# STMP3770 register map
Vendor: Freescale Semiconductor (NXP); Series: STMP37xx; File version: 1.0
CPU: other r0p0, little endian, no MPU, no FPU, 2 interrupt priority bits
Registers are 32-bit, read-write, reset 0x0 unless marked. A register's access mark holds for its fields unless they carry their own. Offsets are from the block's base; [hi:lo] are bit positions.

## SSP1 — 同步串行端口 1(SSP,支持 SD/MMC 卡与 SPI 主/从模式)
Base 0x80010000
Same registers: SSP2 0x80034000
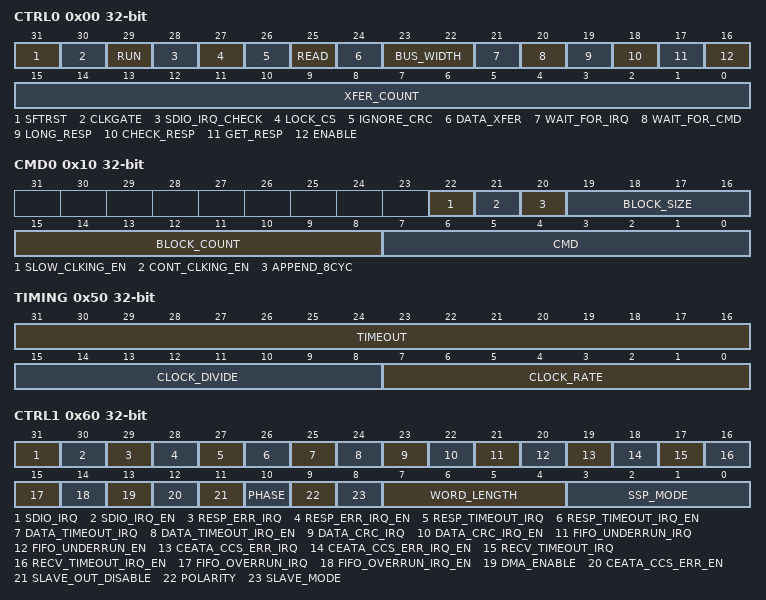
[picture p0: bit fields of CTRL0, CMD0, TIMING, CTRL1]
0x00 CTRL0 — SSP Control Register 0
  [31] SFTRST — SSP Reset. 0=not reset, 1=held in reset. Registers returned to reset state. Min reset time = max(6 APBCLK, 2 SSPCLK) cycles. Bits[31] RW Reset=0x1
  [30] CLKGATE — Gate SSP Clocks. 0=clocks not gated, 1=clocks gated. Set to save power while SSP not actively used. Bits[30] RW Reset=0x1
  [29] RUN — SSP Run. 0=not running, 1=running. Automatically set during DMA operation. Bits[29] RW Reset=0x0
  [28] SDIO_IRQ_CHECK — SD/MMC: enable SDIO IRQ. CE_ATA: 0=ignore CCS, 1=wait for CCS. Must not be 1 if LOCK_CS=1. Bits[28] RW Reset=0x0
  [27] LOCK_CS — SPI: 0=deassert CS, 1=hold CS. SD/MMC: 0=check CRC status, 1=ignore CRC. CE_ATA: disable CCS. If set, DATA_XFER must also be set. Bits[27] RW Reset=0x0
  [26] IGNORE_CRC — Ignore Response CRC in SD/MMC and MS modes. Bits[26] RW Reset=0x0
  [25] READ — Read Mode. When set with DATA_XFER, SSP reads from device. Otherwise SSP writes to device. Bits[25] RW Reset=0x0
  [24] DATA_XFER — Data Transfer Mode. When set, transfers XFER_COUNT bytes of data. MS mode: 1=use FIFOs, 0=use Resp0/Cmd1 registers. Bits[24] RW Reset=0x0
  [23:22] BUS_WIDTH — Data Bus Width. ONE_BIT=0x0, FOUR_BIT=0x1, EIGHT_BIT=0x2. SD/MMC/CE_ATA support all; MS 1/4-bit; SPI 1-bit. Bits[23:22] RW Reset=0x0
    0=ONE_BIT; 1=FOUR_BIT; 2=EIGHT_BIT
  [21] WAIT_FOR_IRQ — MS: wait for card IRQ before TPC. SD/MMC: wait for MMC ready before sending command. Bits[21] RW Reset=0x0
  [20] WAIT_FOR_CMD — SD/MMC: 0=send commands immediately, 1=wait until CRC-checking of data transfer completes. Used to send STOP during multi-block read. Bits[20] RW Reset=0x0
  [19] LONG_RESP — SD/MMC: 0=short response, 1=136-bit long response. Only valid if GET_RESP set. Bits[19] RW Reset=0x0
  [18] CHECK_RESP — SD/MMC/MS: XOR response with REFERENCE, mask with MASK. Mismatch sets RESP_ERR and optionally RESP_ERR_IRQ. Bits[18] RW Reset=0x0
  [17] GET_RESP — SD/MMC/MS: 0=do not wait for card response, 1=command expects response from card. Bits[17] RW Reset=0x0
  [16] ENABLE — SD/MMC/MS Command Transmit Enable. 0=commands disabled, 1=data in Command registers will be sent. Bits[16] RW Reset=0x0
  [15:0] XFER_COUNT — Number of words to transfer per WORD_LENGTH in CTRL1. Run bit and DMA request clear after transfer. SD/MMC: multiple of block size. Bits[15:0] RW Reset=0x1
0x10 CMD0 — SD/MMC and MS Command Register 0
  [22] SLOW_CLKING_EN — SLOW_CLKING_EN。注：PDF第16.11.2节Table 752将bit 31:21标记为RSVD，此字段可能来自后续芯片修订。
  [21] CONT_CLKING_EN — CONT_CLKING_EN。注：PDF第16.11.2节Table 752将bit 31:21标记为RSVD，此字段可能来自后续芯片修订。
  [20] APPEND_8CYC — SD/MMC/CE_ATA: 0=SCK toggles up to 4 cycles idle, 1=8 more cycles. Set to 1 at end of block transfer. Bits[20] RW Reset=0x0
  [19:16] BLOCK_SIZE — SD/MMC block size encode. When BLOCK_COUNT!=0, size = (1<<BLOCK_SIZE). When BLOCK_COUNT=0, ignored. Bits[19:16] RW Reset=0x0
  [15:8] BLOCK_COUNT — SD/MMC block count minus one. Equation: XFER_COUNT = (1<<BLOCK_SIZE)*(BLOCK_COUNT+1). Also SPI control word[15:8]. Bits[15:8] RW Reset=0x0
  [7:0] CMD — SD/MMC Command Index (bits 5:0) or MS TPC[7:0] to send to card. Also SPI control word[7:0]. Includes all standard MMC/SD commands. Bits[7:0] RW Reset=0x0
    0=MMC_GO_IDLE_STATE; 1=MMC_SEND_OP_COND; 2=MMC_ALL_SEND_CID; 3=MMC_SET_RELATIVE_ADDR; 4=MMC_SET_DSR; 5=MMC_RESERVED_5; 6=MMC_SWITCH; 7=MMC_SELECT_DESELECT_CARD; 8=MMC_SEND_EXT_CSD; 9=MMC_SEND_CSD; 10=MMC_SEND_CID; 11=MMC_READ_DAT_UNTIL_STOP; 12=MMC_STOP_TRANSMISSION; 13=MMC_SEND_STATUS; 14=MMC_BUSTEST_R; 15=MMC_GO_INACTIVE_STATE; 16=MMC_SET_BLOCKLEN; 17=MMC_READ_SINGLE_BLOCK; 18=MMC_READ_MULTIPLE_BLOCK; 19=MMC_BUSTEST_W; 20=MMC_WRITE_DAT_UNTIL_STOP; 23=MMC_SET_BLOCK_COUNT; 24=MMC_WRITE_BLOCK; 25=MMC_WRITE_MULTIPLE_BLOCK; 26=MMC_PROGRAM_CID; 27=MMC_PROGRAM_CSD; 28=MMC_SET_WRITE_PROT; 29=MMC_CLR_WRITE_PROT; 30=MMC_SEND_WRITE_PROT; 35=MMC_ERASE_GROUP_START; 36=MMC_ERASE_GROUP_END; 38=MMC_ERASE; 39=MMC_FAST_IO; 40=MMC_GO_IRQ_STATE; 42=MMC_LOCK_UNLOCK; 55=MMC_APP_CMD; 56=MMC_GEN_CMD; 32=SD_ERASE_WR_BLK_START; 33=SD_ERASE_WR_BLK_END; 52=SD_IO_RW_DIRECT; 53=SD_IO_RW_EXTENDED
0x20 CMD1 — SD/MMC Command Register 1
  [31:0] CMD_ARG — SD/MMC or MS Command Argument. Bits[31:0] RW Reset=0x0
0x30 COMPREF — SD/MMC and MS Compare Reference
  [31:0] REFERENCE — SD/MMC/MS compare reference. XOR'd with response when CHECK_RESP set, masked by MASK. Differences indicate error to DMA. Bits[31:0] RW Reset=0x0
0x40 COMPMASK — SD/MMC and MS compare mask
  [31:0] MASK — SD/MMC/MS Compare Mode Mask. Masks result of response vs REFERENCE comparison when CHECK_RESP set. Bits[31:0] RW Reset=0x0
0x50 TIMING — SSP Timing Register
  [31:16] TIMEOUT — Time-Out Counter. SCK cycles * 4096 before asserting DATA TIMEOUT IRQ. Used for SD/MMC and MS data transfer time-out. Bits[31:16] RW Reset=0x0
  [15:8] CLOCK_DIVIDE — Clock Pre-Divider. Must be even value from 2 to 254. Bits[15:8] RW Reset=0x0
  [7:0] CLOCK_RATE — Serial Clock Rate. Bit rate = SSPCLK / (CLOCK_DIVIDE * (1+CLOCK_RATE)). Value from 0 to 255. Bits[7:0] RW Reset=0x0
0x60 CTRL1 — SSP Control Register 1
  [31] SDIO_IRQ — SDIO card interrupt occurred. Write 1 to SET clear address to reset. Bits[31] RW Reset=0x0
  [30] SDIO_IRQ_EN — SDIO Card Interrupt IRQ Enable. 0=masked, 1=IRQs sent to ICOLL. Bits[30] RW Reset=0x0
  [29] RESP_ERR_IRQ — Unexpected response/CRC when CHECK_RESP set. Write 1 to SET clear address to reset. Bits[29] RW Reset=0x0
  [28] RESP_ERR_IRQ_EN — Card Error IRQ Enable. 0=masked, 1=enabled. Asserts CPU IRQ when card error bit set in both Error Mask and R1 response. Bits[28] RW Reset=0x0
  [27] RESP_TIMEOUT_IRQ — Command response time-out occurred. SD/MMC and MS handshake. Write 1 to SET clear address to reset. Bits[27] RW Reset=0x0
  [26] RESP_TIMEOUT_IRQ_EN — Response Time-Out IRQ Enable. 0=masked, 1=enabled. Asserts when no SD/MMC response in 64 cycles or MS not ready in 16 cycles. Bits[26] RW Reset=0x0
  [25] DATA_TIMEOUT_IRQ — Data transmit/receive time-out error IRQ. Counter expired before data bus ready. SD/MMC and MS only. Bits[25] RW Reset=0x0
  [24] DATA_TIMEOUT_IRQ_EN — Data Time-Out Error IRQ Enable. For SD/MMC and MS modes only. Bits[24] RW Reset=0x0
  [23] DATA_CRC_IRQ — Data CRC Error IRQ. For SD/MMC and MS modes only. Write 1 to SET clear address to reset. Bits[23] RW Reset=0x0
  [22] DATA_CRC_IRQ_EN — Data CRC Error IRQ Enable. For SD/MMC and MS modes only. Bits[22] RW Reset=0x0
  [21] FIFO_UNDERRUN_IRQ — FIFO Underrun Interrupt. Set when FIFO read while empty. Write 1 to SET clear address to reset. Bits[21] RW Reset=0x1
  [20] FIFO_UNDERRUN_EN — FIFO Underrun IRQ Enable. IRQ generated if set and FIFO_UNDERRUN_IRQ asserted. Bits[20] RW Reset=0x0
  [19] CEATA_CCS_ERR_IRQ — CE-ATA unexpected CCS error interrupt. Write 1 to SET clear address to reset. Bits[19] RW Reset=0x0
  [18] CEATA_CCS_ERR_IRQ_EN — CE-ATA Unexpected CCS Error Interrupt Enable. 0=disable, 1=enable. Bits[18] RW Reset=0x0
  [17] RECV_TIMEOUT_IRQ — Data Time-Out Interrupt. RX FIFO not empty but not read for 128 HCLK cycles. SPI modes only. Write 1 to SET clear to reset. Bits[17] RW Reset=0x0
  [16] RECV_TIMEOUT_IRQ_EN — Receive Time-Out IRQ Enable. IRQ if RX FIFO not empty and no read for 128 HCLK cycles. Bits[16] RW Reset=0x0
  [15] FIFO_OVERRUN_IRQ — FIFO Overrun Interrupt. Written while full. Write 1 to SET clear address to reset. Bits[15] RW Reset=0x0
  [14] FIFO_OVERRUN_IRQ_EN — FIFO Overrun Interrupt Enable. IRQ if FIFO written while full. Bits[14] RW Reset=0x0
  [13] DMA_ENABLE — DMA Enable. Enables DMA request and command end signals. Bits[13] RW Reset=0x0
  [12] CEATA_CCS_ERR_EN — CE-ATA unexpected CCS error enable. Enables error generation for unexpected CCS. Bits[12] RW Reset=0x0
  [11] SLAVE_OUT_DISABLE — Slave Output Disable. 0=SSP drives MISO in slave mode, 1=does not drive MISO. Bits[11] RW Reset=0x0
  [10] PHASE — Serial Clock Phase. For SPI mode only. Bits[10] RW Reset=0x0
  [9] POLARITY — Serial Clock Polarity. SD/MMC/MS: CMD/TX edge select. MS 1-bit=1, 4-bit=0. SPI: 0=steady 0, 1=steady 1 when idle. Bits[9] RW Reset=0x0
  [8] SLAVE_MODE — Slave Mode. 0=master, 1=slave. Clear to 0 for SD/MMC and MS modes. Bits[8] RW Reset=0x0
  [7:4] WORD_LENGTH — Word Length in bits. 0x0-0x2 reserved, 0x3=4b, 0x7=8b, 0xF=16b. Always 8b in SD/MMC/CE_ATA and MS. Bits[7:4] RW Reset=0x8
    3=FOUR_BITS; 7=EIGHT_BITS; 15=SIXTEEN_BITS
  [3:0] SSP_MODE — Operating Mode. 0x0=SPI, 0x1=TI SSI, 0x3=SD/MMC, 0x4=MS, 0x7=CE_ATA. Soft reset before changing. Bits[3:0] RW Reset=0x0
    0=SPI; 1=SSI; 3=SD_MMC; 4=MS; 7=CE_ATA
0x70 DATA — SSP Data Register
  [31:0] DATA — Data Register. Holds 1-4 words per WORD_LENGTH. Right-justified. Read increments RX FIFO; write increments TX FIFO. Bits[31:0] RW Reset=0x0
0x80 SDRESP0 — SD/MMC Card Response Register 0
  [31:0] RESP0 — SD/MMC Response Status Bits[31:0]. MS mode: device read data. Bits[31:0] RO Reset=0x0
0x90 SDRESP1 — SD/MMC Card Response Register 1
  [31:0] RESP1 — SD/MMC Short Response Command Index[37:32] or Long Response[63:32]. Bits[31:0] RO Reset=0x0
0xA0 SDRESP2 — SD/MMC Card Response Register 2
  [31:0] RESP2 — SD/MMC Long Response[95:64]. Bits[31:0] RO Reset=0x0
0xB0 SDRESP3 — SD/MMC Card Response Register 3
  [31:0] RESP3 — SD/MMC Long Response[127:96]. Bits[31:0] RO Reset=0x0
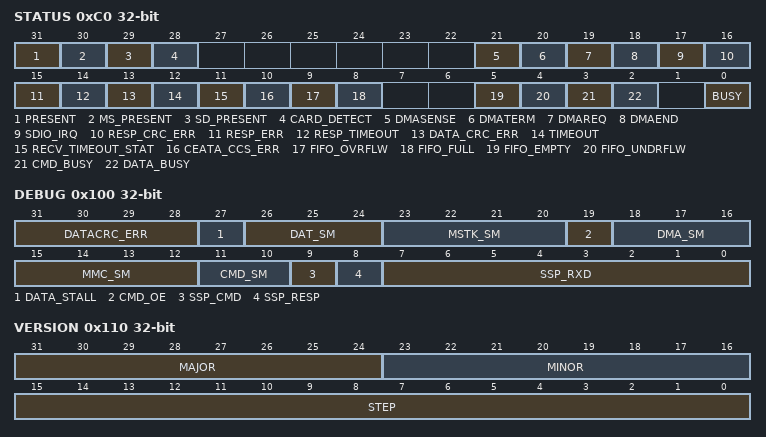
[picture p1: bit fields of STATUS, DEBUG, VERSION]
0xC0 STATUS ro — SSP Status Register
  [31] PRESENT — SSP Present. 0=not present in product, 1=present. Bits[31] RO Reset=0x1
  [30] MS_PRESENT — MS Controller Present. 0=not present, 1=present. Bits[30] RO Reset=0x1
  [29] SD_PRESENT — SD/MMC Controller Present. 0=not present, 1=present. Bits[29] RO Reset=0x1
  [28] CARD_DETECT — Reflects SSP_DETECT input pin state. Bits[28] RO Reset=0x0
  [21] DMASENSE — ssp_dmasense output. Indicates DMA error (time-out/CRC) when high at DMA command end. Bits[21] RO Reset=0x0
  [20] DMATERM — Reflects ssp_dmaterm output port. Toggle signal. Bits[20] RO Reset=0x0
  [19] DMAREQ — Reflects ssp_dmareq output port. Toggle signal. Bits[19] RO Reset=0x0
  [18] DMAEND — Reflects ssp_dmaend output port. Toggle signal. Bits[18] RO Reset=0x0
  [17] SDIO_IRQ — SDIO IRQ detected. Bits[17] RO Reset=0x0
  [16] RESP_CRC_ERR — SD/MMC, MS Response CRC failed. Cleared by soft reset or rising edge of CTRL0_RUN. Bits[16] RO Reset=0x0
  [15] RESP_ERR — Card response with error condition. Cleared by soft reset or rising edge of CTRL0_RUN. Bits[15] RO Reset=0x0
  [14] RESP_TIMEOUT — Response not received in 64 cycles (SD/MMC) or 16 (MS). Cleared by soft reset or CTRL0_RUN rising edge. Bits[14] RO Reset=0x0
  [13] DATA_CRC_ERR — Data CRC Error. Cleared by soft reset or rising edge of CTRL0_RUN. Bits[13] RO Reset=0x0
  [12] TIMEOUT — SD/MMC: time-out before data bus ready. MS: time-out waiting for IRQ. Cleared by soft reset or CTRL0_RUN. Bits[12] RO Reset=0x0
  [11] RECV_TIMEOUT_STAT — Raw receive time-out. RX FIFO non-empty but not read for 128 cycles. Bits[11] RO Reset=0x0
  [10] CEATA_CCS_ERR — Unexpected CCS (CE-ATA Interrupt) occurred. Cleared by soft reset or CTRL0_RUN rising edge. Bits[10] RO Reset=0x0
  [9] FIFO_OVRFLW — FIFO Overflow Interrupt. Bits[9] RO Reset=0x0
  [8] FIFO_FULL — FIFO Full. Bits[8] RO Reset=0x0
  [5] FIFO_EMPTY — FIFO Empty. Bits[5] RO Reset=0x1
  [4] FIFO_UNDRFLW — FIFO Underflow has occurred. Bits[4] RO Reset=0x0
  [3] CMD_BUSY — Command controller busy sending command or receiving response. Bits[3] RO Reset=0x0
  [2] DATA_BUSY — Command controller busy transferring data. Bits[2] RO Reset=0x0
  [0] BUSY — SSP state machines are busy. Bits[0] RO Reset=0x0
0x100 DEBUG ro — SSP Debug Register
  [31:28] DATACRC_ERR — Data CRC error count. Bits[31:28] RO Reset=0x0
  [27] DATA_STALL — MS/MMC: FIFO transfer not ready. Bits[27] RO Reset=0x0
  [26:24] DAT_SM — Data transfer SM: DSM_IDLE=0x0, WORD=0x2, CRC1=0x3, CRC2=0x4, END=0x5. Bits[26:24] RO Reset=0x0
    0=DSM_IDLE; 2=DSM_WORD; 3=DSM_CRC1; 4=DSM_CRC2; 5=DSM_END
  [23:20] MSTK_SM — MS State Machine (15 states). MSTK_IDLE=0x0 to MSTK_DONE=0xE. Includes BS1-3, TPC, HDSHK, RW, CRC, END, DONE. Bits[23:20] RO Reset=0x0
    0=MSTK_IDLE; 1=MSTK_CKON; 2=MSTK_BS1; 3=MSTK_TPC; 4=MSTK_BS2; 5=MSTK_HDSHK; 6=MSTK_BS3; 7=MSTK_RW; 8=MSTK_CRC1; 9=MSTK_CRC2; 10=MSTK_BS0; 11=MSTK_END1; 12=MSTK_END2W; 13=MSTK_END2R; 14=MSTK_DONE
  [19] CMD_OE — Enable for SSP_CMD. Bits[19] RO Reset=0x0
  [18:16] DMA_SM — DMA SM: DMA_IDLE=0x0, DMAREQ=0x1, DMAACK=0x2, STALL=0x3, BUSY=0x4, DONE=0x5, COUNT=0x6. Bits[18:16] RO Reset=0x0
    0=DMA_IDLE; 1=DMA_DMAREQ; 2=DMA_DMAACK; 3=DMA_STALL; 4=DMA_BUSY; 5=DMA_DONE; 6=DMA_COUNT
  [15:12] MMC_SM — MMC SM (11 states): IDLE=0x0 to WAIT=0xA. Includes CMD, TRC, RESP, RPRX, TX, CTOK, RX, CCS, PUP. Bits[15:12] RO Reset=0x0
    0=MMC_IDLE; 1=MMC_CMD; 2=MMC_TRC; 3=MMC_RESP; 4=MMC_RPRX; 5=MMC_TX; 6=MMC_CTOK; 7=MMC_RX; 8=MMC_CCS; 9=MMC_PUP; 10=MMC_WAIT
  [11:10] CMD_SM — MMC Command SM: CSM_IDLE=0x0, INDEX=0x1, ARG=0x2, CRC=0x3. Bits[11:10] RO Reset=0x0
    0=CSM_IDLE; 1=CSM_INDEX; 2=CSM_ARG; 3=CSM_CRC
  [9] SSP_CMD — SSP_CMD signal value. Bits[9] RO Reset=0x0
  [8] SSP_RESP — SSP响应调试值。
  [7:0] SSP_RXD — SSP_RXD signal value. Bits[7:0] RO Reset=0x0
0x110 VERSION ro — SSP Version Register
  [31:24] MAJOR — RTL version MAJOR field. Bits[31:24] RO Reset=0x02
  [23:16] MINOR — RTL version MINOR field. Bits[23:16] RO Reset=0x00
  [15:0] STEP — RTL version stepping field. Bits[15:0] RO Reset=0x0000
